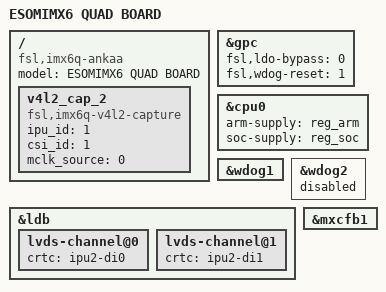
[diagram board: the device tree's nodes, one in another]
/*
 * Copyright 2012=2015 Freescale Semiconductor, Inc.
 * Copyright 2011 Linaro Ltd.
 *
 * The code contained herein is licensed under the GNU General Public
 * License. You may obtain a copy of the GNU General Public License
 * Version 2 or later at the following locations:
 *
 * http://www.opensource.org/licenses/gpl-license.html
 * http://www.gnu.org/copyleft/gpl.html
 */

/dts-v1/;

#include "imx6q.dtsi"
#include "imx6qdlmicro-esomimx6-pollux4.dtsi"

/ {
	model = "ESOMIMX6 QUAD BOARD";
	
	compatible = "fsl,imx6q-ankaa", "fsl,imx6q";

	v4l2_cap_2 {
		compatible = "fsl,imx6q-v4l2-capture";
		ipu_id = <1>;
		csi_id = <1>;
		mclk_source = <0>;
		status = "okay";
	};
};

&gpc {
	/* use ldo-enable, u-boot will check it and configure */
	fsl,ldo-bypass = <0>;
	/* watchdog select of reset source */
	fsl,wdog-reset = <1>;
};

&cpu0 {
	arm-supply = <&reg_arm>;
	soc-supply = <&reg_soc>;
};

&wdog1 {
	status = "okay";
};

&wdog2 {
	status = "disabled";
};

&ldb {
	lvds-channel@0 {
		crtc = "ipu2-di0";
	};
	
	lvds-channel@1 {
		crtc = "ipu2-di1";
	};
};

&mxcfb1 {
	status = "okay";
};


